# STM32U5F9 register map
File version: 1.3
CPU: CM33 r0p1, little endian, MPU, FPU, 4 interrupt priority bits
Registers are 32-bit, read-write, reset 0x0 unless marked. A register's access mark holds for its fields unless they carry their own. Offsets are from the block's base; [hi:lo] are bit positions; lines under a group give offsets from that group; {n}, {i} and the like mark numbered series; 'fields as' and 'values as' point back to an identical list.

## ADC1
Base 0x42028000
Same registers: ADC2 0x42028100, SEC_ADC1 0x52028000, SEC_ADC2 0x52028100
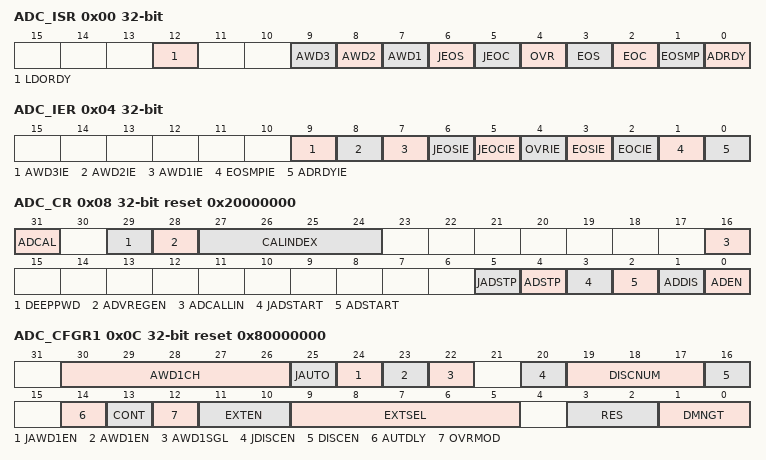
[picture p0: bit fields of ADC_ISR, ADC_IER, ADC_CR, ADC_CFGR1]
0x00 ADC_ISR access per field — ADC interrupt and status register
  [12] LDORDY ro — ADC voltage regulator ready
    0=ADC voltage regulator disabled; 1=ADC voltage regulator enabled
  [9] AWD3 rw — Analog watchdog 3 flag
    0=No analog watchdog 3 event occurred (or the flag event was already acknowledged and cleared by software); 1=Analog watchdog 3 event occurred
  [8] AWD2 rw — Analog watchdog 2 flag
    0=No analog watchdog 2 event occurred (or the flag event was already acknowledged and cleared by software); 1=Analog watchdog 2 event occurred
  [7] AWD1 rw — Analog watchdog 1 flag
    0=No analog watchdog 1 event occurred (or the flag event was already acknowledged and cleared by software); 1=Analog watchdog 1 event occurred
  [6] JEOS rw — Injected channel end of sequence flag
    0=Injected conversion sequence not complete (or the flag event was already acknowledged and cleared by software); 1=Injected conversions complete
  [5] JEOC rw — Injected channel end of conversion flag
    0=Injected channel conversion not complete (or the flag event was already acknowledged and cleared by software); 1=Injected channel conversion complete
  [4] OVR rw — ADC overrun
    0=No overrun occurred (or the flag event was already acknowledged and cleared by software); 1=Overrun has occurred
  [3] EOS rw — End of regular sequence flag
    0=Regular Conversions sequence not complete (or the flag event was already acknowledged and cleared by software); 1=Regular Conversions sequence complete
  [2] EOC rw — End of conversion flag
    0=Regular channel conversion not complete (or the flag event was already acknowledged and cleared by software); 1=Regular channel conversion complete
  [1] EOSMP rw — End of sampling flag
    0=not at the end of the sampling phase (or the flag event was already acknowledged and cleared by software); 1=End of sampling phase reached
  [0] ADRDY rw — ADC ready
    0=ADC not yet ready to start conversion (or the flag event was already acknowledged and cleared by software); 1=ADC is ready to start conversion
0x04 ADC_IER — ADC interrupt enable register
  [9] AWD3IE — Analog watchdog 3 interrupt enable
    0=Analog watchdog 3 interrupt disabled; 1=Analog watchdog 3 interrupt enabled
  [8] AWD2IE — Analog watchdog 2 interrupt enable
    0=Analog watchdog 2 interrupt disabled; 1=Analog watchdog 2 interrupt enabled
  [7] AWD1IE — Analog watchdog 1 interrupt enable
    0=Analog watchdog 1 interrupt disabled; 1=Analog watchdog 1 interrupt enabled
  [6] JEOSIE — End of injected sequence of conversions interrupt enable
    0=JEOS interrupt disabled; 1=JEOS interrupt enabled. An interrupt is generated when the JEOS bit is set.
  [5] JEOCIE — End of injected conversion interrupt enable
    0=JEOC interrupt disabled; 1=JEOC interrupt enabled. An interrupt is generated when the JEOC bit is set.
  [4] OVRIE — Overrun interrupt enable
    0=Overrun interrupt disabled; 1=Overrun interrupt enabled. An interrupt is generated when the OVR bit is set.
  [3] EOSIE — End of regular sequence of conversions interrupt enable
    0=EOS interrupt disabled; 1=EOS interrupt enabled. An interrupt is generated when the EOS bit is set.
  [2] EOCIE — End of regular conversion interrupt enable
    0=EOC interrupt disabled; 1=EOC interrupt enabled. An interrupt is generated when the EOC bit is set.
  [1] EOSMPIE — End of sampling flag interrupt enable for regular conversions
    0=EOSMP interrupt disabled; 1=EOSMP interrupt enabled. An interrupt is generated when the EOSMP bit is set.
  [0] ADRDYIE — ADC ready interrupt enable
    0=ADRDY interrupt disabled; 1=ADRDY interrupt enabled. An interrupt is generated when the ADRDY bit is set.
0x08 ADC_CR reset 0x20000000 — ADC control register
  [31] ADCAL — ADC calibration
    0=Calibration complete; 1=Write 1 to calibrate the ADC. Read at 1 means that a calibration in progress.
  [29] DEEPPWD — Deep-power-down enable
    0=ADC not in deep-power down; 1=ADC in Deep-power-down (default reset state)
  [28] ADVREGEN — ADC voltage regulator enable
    0=ADC Voltage regulator disabled; 1=ADC Voltage regulator enabled
  [27:24] CALINDEX — Calibration factor
    0=Offset calibration factor; {v}=linearity calibration factor {v} (v=1..6); 7=linearity calibration factor 7 and internal offset (write access only); 8=internal offset (read access only)
  [16] ADCALLIN — Linearity calibration
    0=Writing ADCAL launches a calibration without the linearity calibration; 1=Writing ADCAL launches a calibration with he linearity calibration
  [5] JADSTP — ADC stop of injected conversion command
    0=No ADC stop injected conversion command ongoing; 1=Write 1 to stop injected conversions ongoing. Read 1 means that an ADSTP command is in progress.
  [4] ADSTP — ADC stop of regular conversion command
    0=No ADC stop regular conversion command ongoing; 1=Write 1 to stop regular conversions ongoing. Read 1 means that an ADSTP command is in progress.
  [3] JADSTART — ADC start of injected conversion
    0=No ADC injected conversion is ongoing; 1=Write 1 to start injected conversions. Read 1 means that the ADC is operating and eventually converting an injected channel.
  [2] ADSTART — ADC start of regular conversion
    0=No ADC regular conversion is ongoing; 1=Write 1 to start regular conversions. Read 1 means that the ADC is operating and eventually converting a regular channel.
  [1] ADDIS — ADC disable command
    0=no ADDIS command ongoing; 1=Write 1 to disable the ADC. Read 1 means that an ADDIS command is in progress.
  [0] ADEN — ADC enable control
    0=ADC is disabled (OFF state); 1=Write 1 to enable the ADC
0x0C ADC_CFGR1 reset 0x80000000 — ADC configuration register
  [30:26] AWD1CH — Analog watchdog 1 channel selection
    0=ADC analog input channel-0 monitored by AWD1; 1=ADC analog input channel-1 monitored by AWD1; 19=ADC analog input channel-19 monitored by AWD1
  [25] JAUTO — Automatic injected group conversion
    0=Automatic injected group conversion disabled; 1=Automatic injected group conversion enabled
  [24] JAWD1EN — Analog watchdog 1 enable on injected channels
    0=Analog watchdog 1 disabled on injected channels; 1=Analog watchdog 1 enabled on injected channels
  [23] AWD1EN — Analog watchdog 1 enable on regular channels
    0=Analog watchdog 1 disabled on regular channels; 1=Analog watchdog 1 enabled on regular channels
  [22] AWD1SGL — Enable the watchdog 1 on a single channel or on all channels
    0=Analog watchdog 1 enabled on all channels; 1=Analog watchdog 1 enabled on a single channel
  [20] JDISCEN — Discontinuous mode on injected channels
    0=Discontinuous mode on injected channels disabled; 1=Discontinuous mode on injected channels enabled
  [19:17] DISCNUM — Discontinuous mode channel count
    0=1 channel; 1=2 channels; 7=8 channels
  [16] DISCEN — Discontinuous mode for regular channels
    0=Discontinuous mode for regular channels disabled; 1=Discontinuous mode for regular channels enabled
  [14] AUTDLY — Delayed conversion mode
    0=Auto-delayed conversion mode off; 1=Auto-delayed conversion mode on
  [13] CONT — Single / continuous conversion mode for regular conversions
    0=Single conversion mode; 1=Continuous conversion mode
  [12] OVRMOD — Overrun Mode
    0=ADC_DR register is preserved with the old data when an overrun is detected; 1=ADC_DR register is overwritten with the last conversion result when an overrun is detected
  [11:10] EXTEN — External trigger enable and polarity selection for regular channels
    0=Hardware trigger detection disabled (conversions can be launched by software); 1=Hardware trigger detection on the rising edge; 2=Hardware trigger detection on the falling edge; 3=Hardware trigger detection on both the rising and falling edges
  [9:5] EXTSEL — External trigger selection for regular group
    0=adc_ext_trg0; 1=adc_ext_trg1
  [3:2] RES — Data resolution
    0=14 bits; 1=12 bits; 2=10 bits; 3=8bits
  [1:0] DMNGT — Data management configuration
    0=Regular conversion data stored in DR only; 1=DMA One -shot mode selected; 2=MDF mode selected; 3=DMA Circular mode selected
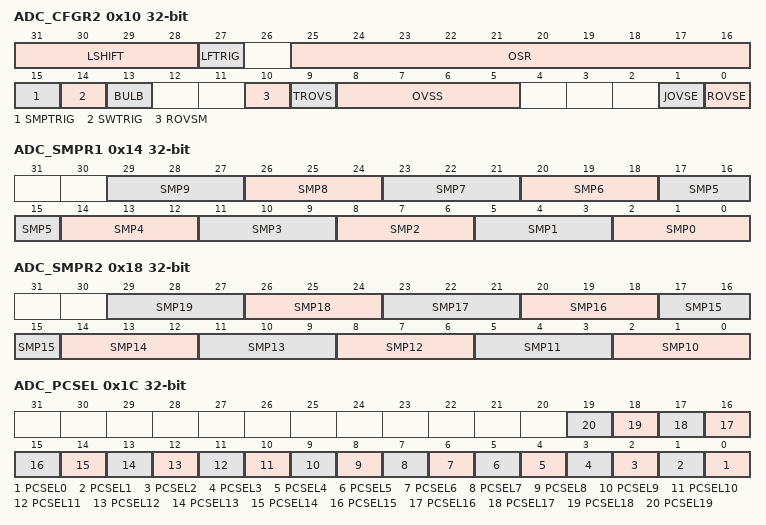
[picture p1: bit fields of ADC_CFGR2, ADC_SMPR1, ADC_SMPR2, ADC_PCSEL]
0x10 ADC_CFGR2 — ADC configuration register 2
  [31:28] LSHIFT — Left shift factor
    0=No left shift; {v}={v}-bit left shift (v=1..15)
  [27] LFTRIG — Low-frequency trigger
    0=Low-frequency trigger mode disabled; 1=Low-frequency trigger mode enabled
  [25:16] OSR — Oversampling ratio
    0=1x (no oversampling); 1=2x
  [15] SMPTRIG — Sampling time control trigger mode
    0=Sampling time control trigger mode disabled; 1=Sampling time control trigger mode enabled
  [14] SWTRIG — Software trigger bit for sampling time control trigger mode
    0=Software trigger starts the conversion for sampling time control trigger mode; 1=Software trigger starts the sampling for sampling time control trigger mode
  [13] BULB — Bulb sampling mode
    0=Bulb sampling mode disabled; 1=Bulb sampling mode enabled. The sampling period starts just after the previous end of the conversion.
  [10] ROVSM — Regular Oversampling mode
    0=Continued mode: When injected conversions are triggered, the oversampling is temporary stopped and continued after the injection sequence (oversampling buffer is maintained during injected sequence); 1=Resumed mode: When injected conversions are triggered, the current oversampling is aborted and resumed from start after the injection sequence (oversampling buffer is zeroed by injected sequence start)
  [9] TROVS — Triggered Regular Oversampling
    0=All oversampled conversions for a channel are done consecutively following a trigger; 1=Each oversampled conversion for a channel needs a new trigger
  [8:5] OVSS — Oversampling right shift
    0=No right shift; {v}={v}-bit right shift (v=1..11)
  [1] JOVSE — Injected Oversampling Enable
    0=Injected oversampling disabled; 1=Injected oversampling enabled
  [0] ROVSE — Regular Oversampling Enable
    0=Regular Oversampling disabled; 1=Regular Oversampling enabled
0x14 ADC_SMPR1 — ADC sample time register 1
  [all] fields
    0=5 ADC clock cycles; 1=6 ADC clock cycles; 2=12 ADC clock cycles; 3=20 ADC clock cycles; 4=36 ADC clock cycles; 5=68 ADC clock cycles; 6=391 ADC clock cycles; 7=814 ADC clock cycles
  [3n+2:3n] SMP{n} (n=0..9) — Channel x sampling time selection (x = 0 to 9)
0x18 ADC_SMPR2 — ADC sample time register 2
  [all] fields
    values as the fields of ADC_SMPR1
  [3n-28:3n-30] SMP{n} (n=10..19) — Channel x sampling time selection (x = 0 to 9)
0x1C ADC_PCSEL — ADC channel preselection register
  [all] fields
    0=Input channel i (VINP[i]) is not preselected for conversion, the ADC conversion of this channel shows a wrong result; 1=Input channel i (VINP[i]) is preselected for conversion
  [n] PCSEL{n} (n=0..19) — Channel i (VINP[i]) preselection
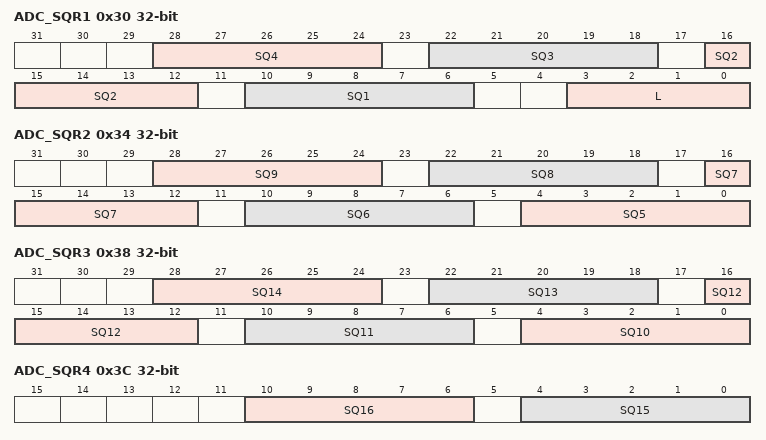
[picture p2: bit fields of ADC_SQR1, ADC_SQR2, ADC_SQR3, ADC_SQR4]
0x30 ADC_SQR1 — ADC regular sequence register 1
  [28:24] SQ4 — 4th conversion in regular sequence
  [22:18] SQ3 — 3rd conversion in regular sequence
  [16:12] SQ2 — 2nd conversion in regular sequence
  [10:6] SQ1 — 1st conversion in regular sequence
  [3:0] L — Regular channel sequence length
    0=1 conversion; 1=2 conversions; 15=16 conversions
0x34 ADC_SQR2 — ADC regular sequence register 2
  [6n-26:6n-30] SQ{n} (n=5..9) — {n}th conversion in regular sequence
0x38 ADC_SQR3 — ADC regular sequence register 3
  [6n-56:6n-60] SQ{n} (n=10..14) — {n}th conversion in regular sequence
0x3C ADC_SQR4 — ADC regular sequence register 4
  [10:6] SQ16 — 16th conversion in regular sequence
  [4:0] SQ15 — 15th conversion in regular sequence
0x40 ADC_DR ro — ADC regular Data Register
  [31:0] RDATA — Regular data converted
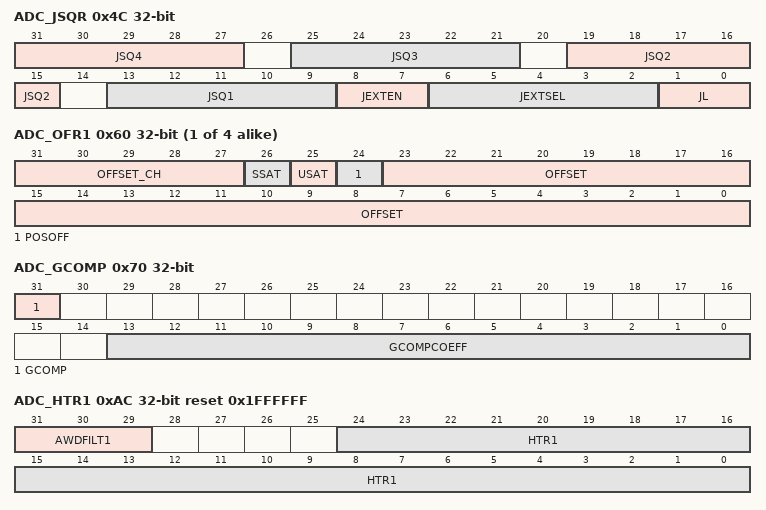
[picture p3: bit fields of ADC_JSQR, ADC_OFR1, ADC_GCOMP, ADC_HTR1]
0x4C ADC_JSQR — ADC injected sequence register
  [31:27] JSQ4 — 4th conversion in the injected sequence
  [25:21] JSQ3 — 3rd conversion in the injected sequence
  [19:15] JSQ2 — 2nd conversion in the injected sequence
  [13:9] JSQ1 — 1st conversion in the injected sequence
  [8:7] JEXTEN — External trigger enable and polarity selection for injected channels
    values as ADC_CFGR1.EXTEN
  [6:2] JEXTSEL — External trigger selection for injected group
    0=adc_jext_trg0; 1=adc_jext_trg1
  [1:0] JL — Injected channel sequence length
    0=1 conversion; 1=2 conversions; 2=3 conversions; 3=4 conversions
{0x5C+4i} ADC_OFR{i} (i=1..4) — ADC offset register
  [31:27] OFFSET_CH — Channel selection for the data offset y
  [26] SSAT — Signed saturation enable
    0=Offset is subtracted maintaining data integrity and extending converted data size (9-bit and 15-bit signed format); 1=Offset is subtracted and result is saturated to maintain converted data size
  [25] USAT — Unsigned saturation enable
    0=Offset is subtracted maintaining data integrity and keeping converted data size; 1=Offset is subtracted and result is saturated to maintain converted data size
  [24] POSOFF — offset sign
    0=Negative offset; 1=Positive offset
  [23:0] OFFSET — Data offset y for the channel programmed into OFFSETy_CH[4:0] bits
0x70 ADC_GCOMP — ADC gain compensation register
  [31] GCOMP — Gain compensation mode
    0=Regular ADC operating mode; 1=Gain compensation enabled and applied on all channels
  [13:0] GCOMPCOEFF — Gain compensation coefficient
    0x800=gain factor of 0.5; 0x1000=gain factor of 1; 0x2000=gain factor of 2; 0x3000=gain factor of 3
{0x7C+4i} ADC_JDR{i} ro (i=1..4) — ADC injected data register
  [31:0] JDATA — Injected data
0xA0 ADC_AWD2CR — ADC analog watchdog 2 configuration register
  [19:0] AWD2CH — Analog watchdog 2 channel selection
0xA4 ADC_AWD3CR — ADC analog watchdog 3 configuration register
  [19:0] AWD3CH — Analog watchdog 3 channel selection
0xA8 ADC_LTR1 — ADC watchdog threshold register 1
  [24:0] LTR1 — Analog watchdog 1 lower threshold
0xAC ADC_HTR1 reset 0x1FFFFFF — ADC watchdog threshold register 1
  [31:29] AWDFILT1 — Analog watchdog filtering parameter
    0=No filtering; 1=two consecutive detection generates an AWDx flag or an interrupt; 7=Eight consecutive detection generates an AWDx flag or an interrupt
  [24:0] HTR1 — Analog watchdog 1 higher threshold
0xB0 ADC_LTR2 — ADC watchdog lower threshold register 2
  [24:0] LTR2 — Analog watchdog 2 lower threshold
0xB4 ADC_HTR2 reset 0x1FFFFFF — ADC watchdog higher threshold register 2
  [24:0] HTR2 — Analog watchdog 2 higher threshold
0xB8 ADC_LTR3 — ADC watchdog lower threshold register 3
  [24:0] LTR3 — Analog watchdog 3 lower threshold
0xBC ADC_HTR3 reset 0x1FFFFFF — ADC watchdog higher threshold register 3
  [24:0] HTR3 — Analog watchdog 3 higher threshold
0xC0 ADC_DIFSEL — ADC differential mode selection register
  [19:0] DIFSEL — Differential mode for channels 19 to 0
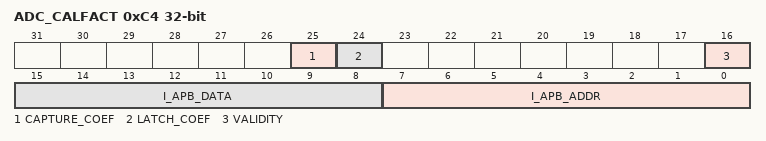
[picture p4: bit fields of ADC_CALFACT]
0xC4 ADC_CALFACT access per field — ADC user control register
  [25] CAPTURE_COEF rw — Calibration factor capture enable bit
    0=Calibration factor not captured; 1=Calibration factor available in CALFACT[31:0] bits, the calibration factor index being defined by CALINDEX[3:0] bits
  [24] LATCH_COEF rw — Calibration factor latch enable bit
    0=No effect; 1=Calibration factor latched in the analog block on LATCH_COEF bit transition from 0 to 1. Prior to latching the calibration factor, CALFACT[31:0] bits must be programmed with the content of CALINDEX[3:0] bits.
  [16] VALIDITY ro — Delayed write access status bit
    0=Operation still in progress; 1=Operation complete
  [15:8] I_APB_DATA ro — Delayed write access data
  [7:0] I_APB_ADDR ro — Delayed write access address
0xC8 ADC_CALFACT2 — ADC calibration factor register
  [31:0] CALFACT — Linearity or offset calibration factor

## Notices in the file
Copyright (c) 2026 STMicroelectronics.
SPDX-License-Identifier: Apache-2.0
Licensed under the Apache License, Version 2.0 (the "License");
you may not use this file except in compliance with the License.
You may obtain a copy of the License at
http://www.apache.org/licenses/LICENSE-2.0
Unless required by applicable law or agreed to in writing, software
distributed under the License is distributed on an "AS IS" BASIS,
WITHOUT WARRANTIES OR CONDITIONS OF ANY KIND, either express or implied.
See the License for the specific language governing permissions and
limitations under the License.
